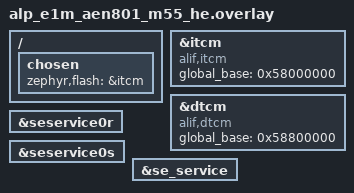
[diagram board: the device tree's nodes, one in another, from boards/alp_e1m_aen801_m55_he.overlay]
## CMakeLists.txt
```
# SPDX-License-Identifier: Apache-2.0
#
# aen-aipm-read -- read the live RUN / STANDBY power+clock operating-point
# profiles (CPU clock Hz, DC-DC rail mV, implementation-defined domain/memory/
# wake masks, flexible-IO rail) through the PORTABLE <alp/power.h> profile
# surface, on the E1M-AEN801 (Ensemble E8, M55-HE), via the bench RAM-run +
# RAM-console flow.
#
# This is the profile-focused companion to aen-se-service-query: same proven,
# READ-ONLY controller-mailbox path, reached through alp_power_profile_get()
# (the SDK's E8 backend maps the SE aiPM ordinals to Hz/mV).  ONLY the
# non-mutating side is called; alp_power_profile_set is deliberately never
# invoked (a wrong power/clock value can brown out the rail) -- see src/main.c.
#
# Plain prj.conf app (no alp_project.py board.yaml emit): the SE-service stack
# Kconfigs (CONFIG_ARM_MHUV2 / CONFIG_HAS_ALIF_SE_SERVICES -- the alp-sdk
# symbols that compile the in-tree MHUv2 IPM driver + hal_alif's se_service.c
# the SDK backend consumes) are sourced under CONFIG_ALP_SDK, which prj.conf
# sets, and the DT nodes are enabled by the board overlay.  See src/main.c +
# the board overlay.

cmake_minimum_required(VERSION 3.20)

# No DTC_OVERLAY_FILE: Zephyr applies boards/<fully-qualified-board>.overlay
# by itself, so the AEN801 and AEN803 targets each read their own file.

find_package(Zephyr REQUIRED HINTS $ENV{ZEPHYR_BASE})
project(aen_aipm_read LANGUAGES C)

target_sources(app PRIVATE src/main.c)
```

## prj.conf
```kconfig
# SPDX-License-Identifier: Apache-2.0
#
# Bench RAM-run config for the E1M-AEN801 (M55-HE). Console is the Alp UART
# console on the E1M edge UART0 (see the console block below).

# Tier-2 driver Kconfigs (incl. CONFIG_ARM_MHUV2 / CONFIG_HAS_ALIF_SE_SERVICES)
# are gated under ALP_SDK.
CONFIG_ALP_SDK=y

# The SE-backed portable backends are registered for the exact E8 silicon_ref.
# Pin the SoC profile so ALP_SOC_REF_STR selects those E8 backends instead of
# the wildcard "*" fallback stub (which is what CONFIG_ALP_SOC_NONE dispatches
# to -- registration alone does not select a backend).
CONFIG_ALP_SOC_ALIF_ENSEMBLE_E8=y

# SE service transport for the SDK's E8 backends.  CONFIG_ARM_MHUV2 builds the
# in-tree "arm,mhuv2" IPM driver (zephyr/drivers/ipm/ipm_arm_mhuv2.c) and pulls
# in CONFIG_IPM; CONFIG_HAS_ALIF_SE_SERVICES compiles the hal_alif SE client
# (se_services/zephyr/src/se_service.c).  The app itself calls only the
# portable alp_power_profile_get / alp_soc_secure_fw_ping; with these two on,
# CONFIG_ALP_SDK_POWER_PROFILE_ALIF_SE + CONFIG_ALP_SDK_SOC_INFO_ALIF_SE
# default y and register the E8 backends behind the portable surface -- but
# registration is not selection, hence CONFIG_ALP_SOC_ALIF_ENSEMBLE_E8 above.
# Both are `default y` under the relevant DT_HAS_*_ENABLED (the overlay okays
# the nodes), but set them explicitly here so the build is self-describing.
CONFIG_ARM_MHUV2=y
CONFIG_HAS_ALIF_SE_SERVICES=y

# Console: Alp UART console -- E1M edge UART0 (Alif UART5, P3_4/P3_5, 115200
# 8N1, NS16550), the E1M-AEN801 carrier console. The board _defconfig already
# selects it; we set it explicitly here so the example is self-describing.
CONFIG_SERIAL=y
CONFIG_CONSOLE=y
CONFIG_UART_CONSOLE=y
CONFIG_UART_INTERRUPT_DRIVEN=y
# Serial-less bench? Comment the four lines above and uncomment these to read
# 'ram_console_buf' over SWD instead:
# CONFIG_RAM_CONSOLE=y
# CONFIG_RAM_CONSOLE_BUFFER_SIZE=2048
# CONFIG_UART_CONSOLE=n
CONFIG_PRINTK=y

# Keep the image small + deterministic for this bench run.
CONFIG_LOG=n
```

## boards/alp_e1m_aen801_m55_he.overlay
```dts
/*
 * Copyright (c) 2026 Alp Lab AB
 * SPDX-License-Identifier: Apache-2.0
 *
 * aen-aipm-read overlay for the E1M-AEN801 (Ensemble E8, M55-HE) RAM-run.
 *
 * The SE SERVICE transport nodes live in the E8 SoC overlay
 * (zephyr/dts/alif/ensemble_e8_peripherals.dtsi) status="disabled" by default
 * (they are SoC-fixed: the RTSS-HE <-> SE MHUv2 mailbox pair + the se_service
 * root node).  This overlay just enables them for the RTSS-HE core:
 *   - seservice0r (arm,mhuv2 @ 0x40040000, IRQ 37, "rx") -- SE -> RTSS inbound
 *   - seservice0s (arm,mhuv2 @ 0x40050000, IRQ 38, "tx") -- RTSS -> SE outbound
 *   - se_service  (alif,secure-enclave-services) -- ties the two via phandles
 *
 * No clocks / pinctrl: the MHUv2 mailboxes are core-internal (no pads, no
 * peripheral clock gate); the driver only maps MMIO + wires the IRQ.
 *
 * SCOPE: this enables the same proven SE-service transport that
 * aen-se-service-query binds, then issues the two ZERO-RISK aiPM reads
 * (get_run_cfg / get_off_cfg) and decodes them.  No STOC/fuse/lifecycle/power
 * WRITE is performed.  See the app header + src/main.c.
 */

/*
 * RAM-run: retarget ROM to ITCM (path-reference form &itcm; the phandle-array
 * form makes FLASH_SIZE=0 and overflows the link) -- the aen-se-service-query
 * precedent.
 */
/ {
	chosen {
		zephyr,flash = &itcm;
		/delete-property/ zephyr,code-partition;
	};
};

/*
 * itcm/dtcm `global_base` for local_to_global() -- hal_alif se_service.c puts
 * its outbound SE message buffer through local_to_global() (soc_memory_map.h),
 * which reads DT_PROP(itcm/dtcm, global_base) to translate the M55-local
 * address into the global view the SE's DMA sees.  Upstream Zephyr's
 * arm,itcm/arm,dtcm bindings have no such prop, so re-`compatible` the nodes
 * onto the alp-sdk alif,itcm/alif,dtcm bindings (which declare global_base) and
 * set the E8 RTSS-HE global TCM aliases (ITCM 0x58000000, DTCM 0x58800000),
 * transcribed from the Apache-2.0 zephyr_alif fork ensemble_rtss_he.dtsi -- the
 * same values the NPU + camera + eth local_to_global paths use.
 */
&itcm {
	compatible = "alif,itcm";
	global_base = <0x58000000>;
};

&dtcm {
	compatible = "alif,dtcm";
	global_base = <0x58800000>;
};

&seservice0r {
	status = "okay";
};

&seservice0s {
	status = "okay";
};

&se_service {
	status = "okay";
};
```

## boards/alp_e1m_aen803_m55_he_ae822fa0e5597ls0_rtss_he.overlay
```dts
/*
 * Copyright (c) 2026 Alp Lab AB
 * SPDX-License-Identifier: Apache-2.0
 *
 * aen-aipm-read overlay for the E1M-AEN803 (Ensemble E8, M55-HE) RAM-run.
 *
 * The SE SERVICE transport nodes live in the E8 SoC overlay
 * (zephyr/dts/alif/ensemble_e8_peripherals.dtsi) status="disabled" by default
 * (they are SoC-fixed: the RTSS-HE <-> SE MHUv2 mailbox pair + the se_service
 * root node).  This overlay just enables them for the RTSS-HE core:
 *   - seservice0r (arm,mhuv2 @ 0x40040000, IRQ 37, "rx") -- SE -> RTSS inbound
 *   - seservice0s (arm,mhuv2 @ 0x40050000, IRQ 38, "tx") -- RTSS -> SE outbound
 *   - se_service  (alif,secure-enclave-services) -- ties the two via phandles
 *
 * No clocks / pinctrl: the MHUv2 mailboxes are core-internal (no pads, no
 * peripheral clock gate); the driver only maps MMIO + wires the IRQ.
 *
 * SCOPE: this enables the same proven SE-service transport that
 * aen-se-service-query binds, then issues the two ZERO-RISK aiPM reads
 * (get_run_cfg / get_off_cfg) and decodes them.  No STOC/fuse/lifecycle/power
 * WRITE is performed.  See the app header + src/main.c.
 */

/*
 * RAM-run: retarget ROM to ITCM (path-reference form &itcm; the phandle-array
 * form makes FLASH_SIZE=0 and overflows the link) -- the aen-se-service-query
 * precedent.
 */
/ {
	chosen {
		zephyr,flash = &itcm;
		/delete-property/ zephyr,code-partition;
	};
};

/*
 * itcm/dtcm `global_base` for local_to_global() -- hal_alif se_service.c puts
 * its outbound SE message buffer through local_to_global() (soc_memory_map.h),
 * which reads DT_PROP(itcm/dtcm, global_base) to translate the M55-local
 * address into the global view the SE's DMA sees.  Upstream Zephyr's
 * arm,itcm/arm,dtcm bindings have no such prop, so re-`compatible` the nodes
 * onto the alp-sdk alif,itcm/alif,dtcm bindings (which declare global_base) and
 * set the E8 RTSS-HE global TCM aliases (ITCM 0x58000000, DTCM 0x58800000),
 * transcribed from the Apache-2.0 zephyr_alif fork ensemble_rtss_he.dtsi -- the
 * same values the NPU + camera + eth local_to_global paths use.
 */
&itcm {
	compatible = "alif,itcm";
	global_base = <0x58000000>;
};

&dtcm {
	compatible = "alif,dtcm";
	global_base = <0x58800000>;
};

&seservice0r {
	status = "okay";
};

&seservice0s {
	status = "okay";
};

&se_service {
	status = "okay";
};
```

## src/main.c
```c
/*
 * Copyright (c) 2026 Alp Lab AB
 * SPDX-License-Identifier: Apache-2.0
 *
 * aen-aipm-read -- read the live RUN and STANDBY power/clock operating-point
 * profiles through the PORTABLE <alp/power.h> profile surface on the
 * E1M-AEN801 (Ensemble E8, M55-HE), via the bench RAM-run + RAM-console flow.
 *
 * WHAT THE PROFILE SURFACE IS.  On SoCs like the E8 a system-controller
 * firmware owns the power and clock tree: a core never pokes PLL / DC-DC /
 * power-domain registers, it reads and writes a per-core operating-point
 * PROFILE instead (on the E8 that controller is the Secure Enclave and the
 * feature is aiPM -- Autonomous Intelligent Power Management).  The portable
 * surface exposes the two profiles every such platform keeps:
 *
 *   - ALP_POWER_PROFILE_RUN     -- the active operating point: CPU clock (Hz),
 *     core DC-DC rail (mV), which power domains / memory blocks stay powered,
 *     and the flexible-IO rail.
 *   - ALP_POWER_PROFILE_STANDBY -- the standby/off operating point plus the
 *     wake-event configuration.
 *
 * WHAT THIS APP DOES.  It calls alp_power_profile_get() for both profiles and
 * prints every portable field.  Frequencies arrive in Hz and rails in mV (the
 * backend maps the controller's ordinal encodings); the power_domains /
 * memory_blocks / wake_events bitmasks are IMPLEMENTATION-DEFINED (their bit
 * legends are SoC business, documented in the per-SoM HW reference), so this
 * app prints them raw -- portable code treats them as opaque tokens.
 *
 * SAFETY -- READ-ONLY.  alp_power_profile_get() never changes the operating
 * point.  Its mutating companion alp_power_profile_set() is DELIBERATELY NOT
 * CALLED: a wrong rail/clock value can brown out the rail or stall the core,
 * so profile writes need known-good target values from the per-SoM HW
 * reference + a recovery plan before any bench run (see the <alp/power.h>
 * warning).  alp_soc_secure_fw_ping() (<alp/hw_info.h>) runs first as the
 * liveness gate, exactly like the original heartbeat did.
 *
 * Both getters ride a bounded controller-mailbox round-trip, so the app never
 * hangs.  PASS gate: ping + both profile reads return ALP_OK.
 *
 * On builds without a profile-capable backend (native_sim, SoMs whose power
 * tree the application core owns directly) the same code links and runs; the
 * calls report ALP_ERR_NOSUPPORT and the app says so -- the portable-surface
 * contract this example exists to demonstrate.
 */

#include <stdbool.h>
#include <stdint.h>

#include <zephyr/kernel.h>
#include <zephyr/sys/printk.h>

#include <alp/hw_info.h>
#include <alp/power.h>

static void print_profile(const char *name, const alp_power_profile_t *p, bool standby)
{
	printk("        cpu_clk_hz     = %u  (%u.%u MHz)\n",
	       p->cpu_clk_hz,
	       p->cpu_clk_hz / 1000000U,
	       (p->cpu_clk_hz % 1000000U) / 100000U);
	printk("        rail_mv        = %u mV\n", p->rail_mv);
	printk("        power_domains  = 0x%08x  (implementation-defined legend)\n", p->power_domains);
	printk("        memory_blocks  = 0x%08x  (implementation-defined legend)\n", p->memory_blocks);
	if (standby) {
		printk("        wake_events    = 0x%08x  (implementation-defined legend)\n",
		       p->wake_events);
	}
	printk("        io_mv          = %u mV\n", p->io_mv);
	(void)name;
}

int main(void)
{
	alp_status_t rc;
	bool         all_ok = true;

	printk("\n=== aen-aipm-read (portable operating-point profiles, read-only) ===\n");

	/*
	 * 0. Liveness: prove the platform's power/identity controller answers
	 *    before we trust the profile reads.
	 */
	rc = alp_soc_secure_fw_ping();
	printk("secure_fw_ping       : rc=%d\n", (int)rc);
	all_ok &= (rc == ALP_OK);

	/*
	 * 1. RUN profile -- the live operating point.  Read-only; nothing is
	 *    written.
	 */
	alp_power_profile_t run = { 0 };

	rc = alp_power_profile_get(ALP_POWER_PROFILE_RUN, &run);
	printk("profile_get(RUN)     : rc=%d\n", (int)rc);
	all_ok &= (rc == ALP_OK);
	if (rc == ALP_OK) {
		print_profile("RUN", &run, false);
	}

	/*
	 * 2. STANDBY profile -- the standby/off operating point + wake
	 *    configuration.  Read-only; nothing is written.
	 */
	alp_power_profile_t stby = { 0 };

	rc = alp_power_profile_get(ALP_POWER_PROFILE_STANDBY, &stby);
	printk("profile_get(STANDBY) : rc=%d\n", (int)rc);
	all_ok &= (rc == ALP_OK);
	if (rc == ALP_OK) {
		print_profile("STANDBY", &stby, true);
	}

	if (all_ok) {
		printk("RESULT PASS: portable profile surface returned RUN+STANDBY read-only "
		       "(RUN %u.%u MHz @ %u mV; STANDBY %u mV) -- alp_power_profile_set never "
		       "called\n",
		       run.cpu_clk_hz / 1000000U,
		       (run.cpu_clk_hz % 1000000U) / 100000U,
		       run.rail_mv,
		       stby.rail_mv);
	} else {
		printk("RESULT FAIL: ping or a profile read did not return ALP_OK "
		       "(NOSUPPORT = no profile-capable backend on this build; NOT_READY = "
		       "controller asleep/unreachable on this boot) -- see the per-call rc "
		       "above\n");
	}

	return 0;
}
```
